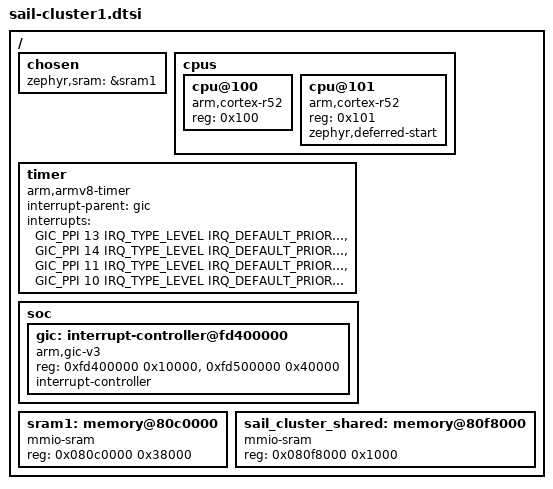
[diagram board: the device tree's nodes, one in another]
/*
 * Copyright The Zephyr Project Contributors
 * SPDX-License-Identifier: Apache-2.0
 */

/*
 * Image for cluster 1, started by the cluster-0 image. Cluster 1 has its own
 * interrupt controller. The top SRAM page is shared with the cluster-0 image.
 */

/delete-node/ &sram0;
/delete-node/ &sail_mbox_rx;
/delete-node/ &gic;

/ {
	chosen {
		zephyr,sram = &sram1;
	};

	cpus {
		/delete-node/ cpu@0;

		cpu@100 {
			compatible = "arm,cortex-r52";
			reg = <0x100>;
			device_type = "cpu";
		};

		cpu@101 {
			compatible = "arm,cortex-r52";
			reg = <0x101>;
			device_type = "cpu";
			zephyr,deferred-start;
		};
	};

	timer {
		compatible = "arm,armv8-timer";
		interrupt-parent = <&gic>;
		interrupts = <GIC_PPI 13 IRQ_TYPE_LEVEL IRQ_DEFAULT_PRIORITY>,
			     <GIC_PPI 14 IRQ_TYPE_LEVEL IRQ_DEFAULT_PRIORITY>,
			     <GIC_PPI 11 IRQ_TYPE_LEVEL IRQ_DEFAULT_PRIORITY>,
			     <GIC_PPI 10 IRQ_TYPE_LEVEL IRQ_DEFAULT_PRIORITY>;
	};

	soc {
		gic: interrupt-controller@fd400000 {
			compatible = "arm,gic-v3", "arm,gic";
			reg = <0xfd400000 0x10000>,
			      <0xfd500000 0x40000>;
			interrupt-controller;
			#interrupt-cells = <4>;
			status = "okay";
		};
	};

	sram1: memory@80c0000 {
		compatible = "mmio-sram";
		reg = <0x080c0000 0x38000>;
	};

	sail_cluster_shared: memory@80f8000 {
		compatible = "mmio-sram";
		reg = <0x080f8000 0x1000>;
	};
};
